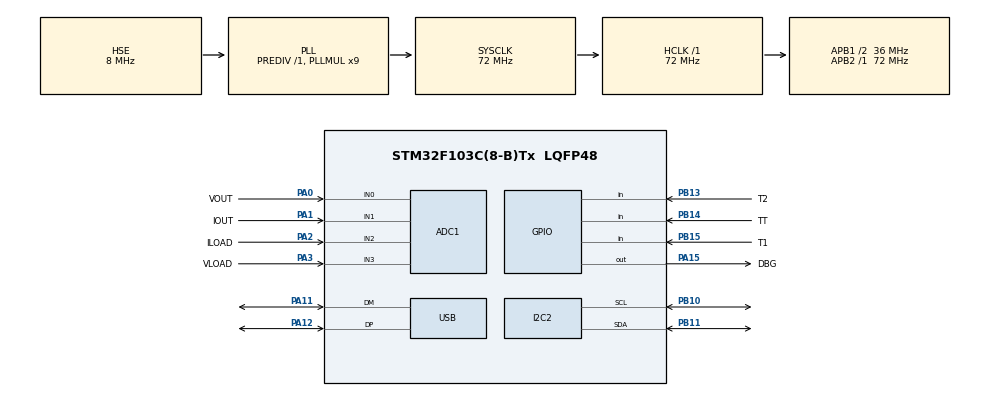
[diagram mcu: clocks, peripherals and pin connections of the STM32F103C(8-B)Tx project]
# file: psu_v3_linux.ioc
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ADC1.Channel-0\#ChannelRegularConversion=ADC_CHANNEL_0
ADC1.ContinuousConvMode=DISABLE
ADC1.DataAlign=ADC_DATAALIGN_RIGHT
ADC1.DiscontinuousConvMode=DISABLE
ADC1.EnableAnalogWatchDog=false
ADC1.EnableRegularConversion=ENABLE
ADC1.ExternalTrigConv=ADC_SOFTWARE_START
ADC1.InjNumberOfConversion=0
ADC1.NbrOfConversion=1
ADC1.NbrOfConversionFlag=1
ADC1.Rank-0\#ChannelRegularConversion=1
ADC1.SamplingTime-0\#ChannelRegularConversion=ADC_SAMPLETIME_1CYCLE_5
ADC1.ScanConvMode=ADC_SCAN_DISABLE
ADC1.master=1
FREERTOS.Tasks01=defaultTask,0,128,StartDefaultTask,Default,NULL
Mcu.Family=STM32F1
Mcu.Name=STM32F103C(8-B)Tx
Mcu.Package=LQFP48
NVIC.PriorityGroup=NVIC_PRIORITYGROUP_4
NVIC.TIM4_IRQn=true\:0\:0\:false\:false\:true\:false\:true\:true
NVIC.TimeBase=TIM4_IRQn
NVIC.TimeBaseIP=TIM4
NVIC.USB_LP_CAN1_RX0_IRQn=true\:5\:0\:false\:false\:true\:true\:false\:true
PA0-WKUP.GPIO_Label=VOUT
PA0-WKUP.Signal=ADCx_IN0
PA1.GPIO_Label=IOUT
PA1.Signal=ADCx_IN1
PA11.Mode=Device
PA11.Signal=USB_DM
PA12.Mode=Device
PA12.Signal=USB_DP
PA13.Mode=Serial_Wire
PA13.Signal=SYS_JTMS-SWDIO
PA14.Mode=Serial_Wire
PA14.Signal=SYS_JTCK-SWCLK
PA15.GPIO_Label=DBG
PA15.Signal=GPIO_Output
PA2.GPIO_Label=ILOAD
PA2.Signal=ADCx_IN2
PA3.GPIO_Label=VLOAD
PA3.Signal=ADCx_IN3
PB10.Mode=I2C
PB10.Signal=I2C2_SCL
PB11.Mode=I2C
PB11.Signal=I2C2_SDA
PB13.GPIO_Label=T2
PB13.GPIO_PuPd=GPIO_PULLUP
PB13.Signal=GPIO_Input
PB14.GPIO_Label=TT
PB14.GPIO_PuPd=GPIO_PULLUP
PB14.Signal=GPIO_Input
PB15.GPIO_Label=T1
PB15.GPIO_PuPd=GPIO_PULLUP
PB15.Signal=GPIO_Input
PD0-OSC_IN.Mode=HSE-External-Oscillator
PD0-OSC_IN.Signal=RCC_OSC_IN
PD1-OSC_OUT.Mode=HSE-External-Oscillator
PD1-OSC_OUT.Signal=RCC_OSC_OUT
ProjectManager.HeapSize=0x200
ProjectManager.StackSize=0x400
ProjectManager.TargetToolchain=Makefile
RCC.ADCPresc=RCC_ADCPCLK2_DIV6
RCC.AHBFreq_Value=72000000
RCC.APB1CLKDivider=RCC_HCLK_DIV2
RCC.APB1Freq_Value=36000000
RCC.APB1TimFreq_Value=72000000
RCC.APB2Freq_Value=72000000
RCC.APB2TimFreq_Value=72000000
RCC.HCLKFreq_Value=72000000
RCC.PLLMUL=RCC_PLL_MUL9
RCC.PLLSourceVirtual=RCC_PLLSOURCE_HSE
RCC.SYSCLKFreq_VALUE=72000000
RCC.SYSCLKSource=RCC_SYSCLKSOURCE_PLLCLK
RCC.USBFreq_Value=48000000
RCC.USBPrescaler=RCC_USBCLKSOURCE_PLL_DIV1_5
SH.ADCx_IN0.0=ADC1_IN0,IN0
SH.ADCx_IN1.0=ADC1_IN1,IN1
SH.ADCx_IN2.0=ADC1_IN2,IN2
SH.ADCx_IN3.0=ADC1_IN3,IN3
USB_DEVICE.APP_RX_DATA_SIZE=128
USB_DEVICE.APP_TX_DATA_SIZE=128
USB_DEVICE.CLASS_NAME_FS=CDC
USB_DEVICE.USBD_MAX_NUM_INTERFACES=1
USB_DEVICE.VirtualMode=Cdc
USB_DEVICE.VirtualModeFS=Cdc_FS
VP_FREERTOS_VS_CMSIS_V1.Mode=CMSIS_V1
VP_SYS_VS_tim4.Mode=TIM4
VP_USB_DEVICE_VS_USB_DEVICE_CDC_FS.Mode=CDC_FS
board=psu_v3_linux

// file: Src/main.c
/* USER CODE BEGIN Header */
/**
  ******************************************************************************
  * @file           : main.c
  * @brief          : Main program body
  ******************************************************************************
  * @attention
  *
  * <h2><center>&copy; Copyright (c) 2019 STMicroelectronics.
  * All rights reserved.</center></h2>
  *
  * This software component is licensed by ST under Ultimate Liberty license
  * SLA0044, the "License"; You may not use this file except in compliance with
  * the License. You may obtain a copy of the License at:
  *                             www.st.com/SLA0044
  *
  ******************************************************************************
  */
/* USER CODE END Header */

#include "main.h"
#include "cmsis_os.h"
#include "usb_device.h"

/* USER CODE BEGIN Includes */
#include "board.h"
#include "usbd_cdc_if.h"
/* USER CODE END Includes */

ADC_HandleTypeDef hadc1;

I2C_HandleTypeDef hi2c2;
DMA_HandleTypeDef hdma_i2c2_tx;

osThreadId defaultTaskHandle;
/* USER CODE BEGIN PV */
/* Private variables ---------------------------------------------------------*/
extern uint32_t g_pfnVectors;
/* USER CODE END PV */

void SystemClock_Config(void);
static void MX_GPIO_Init(void);
static void MX_DMA_Init(void);
static void MX_I2C2_Init(void);
static void MX_ADC1_Init(void);
void StartDefaultTask(void const * argument);

/* USER CODE BEGIN PFP */
/* Private function prototypes -----------------------------------------------*/
void psu(void);

/* USER CODE END PFP */

int main(void)
{
  /* USER CODE BEGIN 1 */
	/*
		PB10 -> SCL (LCD_CD)
		PB11 -> SDA (LCD_LED)
    */

  /* Vector Table Relocation to startup vector table  */
  SCB->VTOR = (uint32_t)(&g_pfnVectors) & 0xFFFF;
  reenumerate_usb();
  /* USER CODE END 1 */

  /* MCU Configuration--------------------------------------------------------*/

  /* Reset of all peripherals, Initializes the Flash interface and the Systick. */
  HAL_Init();

  /* Configure the system clock */
  SystemClock_Config();

  /* Initialize all configured peripherals */
  MX_GPIO_Init();
  MX_DMA_Init();
  MX_I2C2_Init();
  MX_ADC1_Init();

  /* Create the thread(s) */
  /* definition and creation of defaultTask */
  osThreadDef(defaultTask, StartDefaultTask, osPriorityNormal, 0, 128);
  defaultTaskHandle = osThreadCreate(osThread(defaultTask), NULL);

  /* Start scheduler */
  osKernelStart();

  /* We should never get here as control is now taken by the scheduler */

  /* Infinite loop */
  while (1)
  {

  }
}

void SystemClock_Config(void)
{
  RCC_OscInitTypeDef RCC_OscInitStruct = {0};
  RCC_ClkInitTypeDef RCC_ClkInitStruct = {0};
  RCC_PeriphCLKInitTypeDef PeriphClkInit = {0};

  /** Initializes the CPU, AHB and APB busses clocks
  */
  RCC_OscInitStruct.OscillatorType = RCC_OSCILLATORTYPE_HSE;
  RCC_OscInitStruct.HSEState = RCC_HSE_ON;
  RCC_OscInitStruct.HSEPredivValue = RCC_HSE_PREDIV_DIV1;
  RCC_OscInitStruct.HSIState = RCC_HSI_ON;
  RCC_OscInitStruct.PLL.PLLState = RCC_PLL_ON;
  RCC_OscInitStruct.PLL.PLLSource = RCC_PLLSOURCE_HSE;
  RCC_OscInitStruct.PLL.PLLMUL = RCC_PLL_MUL9;
  if (HAL_RCC_OscConfig(&RCC_OscInitStruct) != HAL_OK)
  {
    Error_Handler();
  }
  /** Initializes the CPU, AHB and APB busses clocks
  */
  RCC_ClkInitStruct.ClockType = RCC_CLOCKTYPE_HCLK|RCC_CLOCKTYPE_SYSCLK
                              |RCC_CLOCKTYPE_PCLK1|RCC_CLOCKTYPE_PCLK2;
  RCC_ClkInitStruct.SYSCLKSource = RCC_SYSCLKSOURCE_PLLCLK;
  RCC_ClkInitStruct.AHBCLKDivider = RCC_SYSCLK_DIV1;
  RCC_ClkInitStruct.APB1CLKDivider = RCC_HCLK_DIV2;
  RCC_ClkInitStruct.APB2CLKDivider = RCC_HCLK_DIV1;

  if (HAL_RCC_ClockConfig(&RCC_ClkInitStruct, FLASH_LATENCY_2) != HAL_OK)
  {
    Error_Handler();
  }
  PeriphClkInit.PeriphClockSelection = RCC_PERIPHCLK_ADC|RCC_PERIPHCLK_USB;
  PeriphClkInit.AdcClockSelection = RCC_ADCPCLK2_DIV6;
  PeriphClkInit.UsbClockSelection = RCC_USBCLKSOURCE_PLL_DIV1_5;
  if (HAL_RCCEx_PeriphCLKConfig(&PeriphClkInit) != HAL_OK)
  {
    Error_Handler();
  }
}

static void MX_ADC1_Init(void)
{

  ADC_ChannelConfTypeDef sConfig = {0};

  /** Common config
  */
  hadc1.Instance = ADC1;
  hadc1.Init.ScanConvMode = ADC_SCAN_DISABLE;
  hadc1.Init.ContinuousConvMode = DISABLE;
  hadc1.Init.DiscontinuousConvMode = DISABLE;
  hadc1.Init.ExternalTrigConv = ADC_SOFTWARE_START;
  hadc1.Init.DataAlign = ADC_DATAALIGN_RIGHT;
  hadc1.Init.NbrOfConversion = 1;
  if (HAL_ADC_Init(&hadc1) != HAL_OK)
  {
    Error_Handler();
  }
  /** Configure Regular Channel
  */
  sConfig.Channel = ADC_CHANNEL_0;
  sConfig.Rank = ADC_REGULAR_RANK_1;
  sConfig.SamplingTime = ADC_SAMPLETIME_1CYCLE_5;
  if (HAL_ADC_ConfigChannel(&hadc1, &sConfig) != HAL_OK)
  {
    Error_Handler();
  }

}

static void MX_I2C2_Init(void)
{

  hi2c2.Instance = I2C2;
  hi2c2.Init.ClockSpeed = 100000;
  hi2c2.Init.DutyCycle = I2C_DUTYCYCLE_2;
  hi2c2.Init.OwnAddress1 = 0;
  hi2c2.Init.AddressingMode = I2C_ADDRESSINGMODE_7BIT;
  hi2c2.Init.DualAddressMode = I2C_DUALADDRESS_DISABLE;
  hi2c2.Init.OwnAddress2 = 0;
  hi2c2.Init.GeneralCallMode = I2C_GENERALCALL_DISABLE;
  hi2c2.Init.NoStretchMode = I2C_NOSTRETCH_DISABLE;
  if (HAL_I2C_Init(&hi2c2) != HAL_OK)
  {
    Error_Handler();
  }

}

static void MX_DMA_Init(void)
{

  /* DMA controller clock enable */
  __HAL_RCC_DMA1_CLK_ENABLE();

  /* DMA interrupt init */
  /* DMA1_Channel4_IRQn interrupt configuration */
  HAL_NVIC_SetPriority(DMA1_Channel4_IRQn, 5, 0);
  HAL_NVIC_EnableIRQ(DMA1_Channel4_IRQn);

}

static void MX_GPIO_Init(void)
{
  GPIO_InitTypeDef GPIO_InitStruct = {0};

  /* GPIO Ports Clock Enable */
  __HAL_RCC_GPIOD_CLK_ENABLE();
  __HAL_RCC_GPIOA_CLK_ENABLE();
  __HAL_RCC_GPIOB_CLK_ENABLE();

  /*Configure GPIO pin Output Level */
  HAL_GPIO_WritePin(DBG_GPIO_Port, DBG_Pin, GPIO_PIN_RESET);

  /*Configure GPIO pin : DBG_Pin */
  GPIO_InitStruct.Pin = DBG_Pin;
  GPIO_InitStruct.Mode = GPIO_MODE_OUTPUT_PP;
  GPIO_InitStruct.Pull = GPIO_NOPULL;
  GPIO_InitStruct.Speed = GPIO_SPEED_FREQ_LOW;
  HAL_GPIO_Init(DBG_GPIO_Port, &GPIO_InitStruct);

  /*Configure GPIO pins : T2_Pin TT_Pin T1_Pin */
  GPIO_InitStruct.Pin = T2_Pin|TT_Pin|T1_Pin;
  GPIO_InitStruct.Mode = GPIO_MODE_INPUT;
  GPIO_InitStruct.Pull = GPIO_PULLUP;
  HAL_GPIO_Init(GPIOB, &GPIO_InitStruct);

}

void StartDefaultTask(void const * argument)
{

  /* init code for USB_DEVICE */
  MX_USB_DEVICE_Init();

  /* USER CODE BEGIN 5 */
  /* Infinite loop */
    psu();
    vTaskDelete( NULL );
  /* USER CODE END 5 */
}

void HAL_TIM_PeriodElapsedCallback(TIM_HandleTypeDef *htim)
{
  if (htim->Instance == TIM4) {
    HAL_IncTick();
  }
}

void Error_Handler(void)
{
  while(1)
  {
  }
}

/************************ (C) COPYRIGHT STMicroelectronics *****END OF FILE****/
